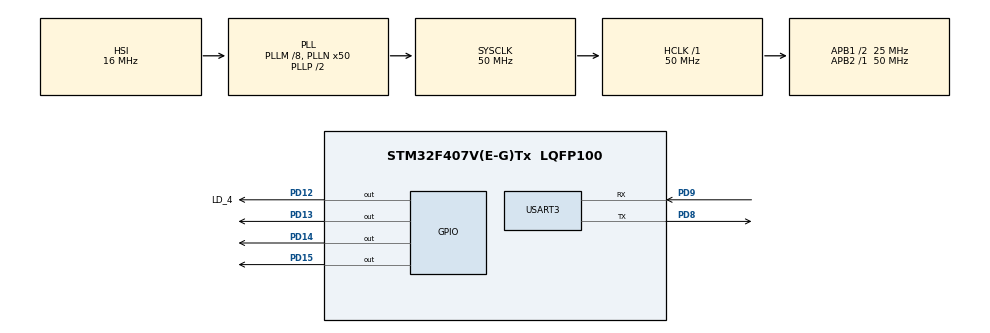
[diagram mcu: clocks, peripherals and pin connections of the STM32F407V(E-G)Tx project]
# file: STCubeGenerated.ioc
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Mcu.Family=STM32F4
Mcu.Name=STM32F407V(E-G)Tx
Mcu.Package=LQFP100
NVIC.PriorityGroup=NVIC_PRIORITYGROUP_4
NVIC.TIM3_IRQn=true\:0\:0\:false\:false\:true\:true\:true
PD12.GPIO_Label=LD_4
PD12.Signal=GPIO_Output
PD13.Signal=GPIO_Output
PD14.Signal=GPIO_Output
PD15.Signal=GPIO_Output
PD8.Mode=Asynchronous
PD8.Signal=USART3_TX
PD9.Mode=Asynchronous
PD9.Signal=USART3_RX
ProjectManager.HeapSize=0x200
ProjectManager.StackSize=0x400
ProjectManager.TargetToolchain=MDK-ARM V5
RCC.48MHZClocksFreq_Value=25000000
RCC.AHBFreq_Value=50000000
RCC.APB1CLKDivider=RCC_HCLK_DIV2
RCC.APB1Freq_Value=25000000
RCC.APB1TimFreq_Value=50000000
RCC.APB2Freq_Value=50000000
RCC.APB2TimFreq_Value=50000000
RCC.CortexFreq_Value=50000000
RCC.HCLKFreq_Value=50000000
RCC.HSE_VALUE=25000000
RCC.HSI_VALUE=16000000
RCC.LSE_VALUE=32768
RCC.PLLM=8
RCC.PLLN=50
RCC.SYSCLKFreq_VALUE=50000000
RCC.SYSCLKSource=RCC_SYSCLKSOURCE_PLLCLK
RCC.VCOOutputFreq_Value=100000000
USART3.VirtualMode=VM_ASYNC
VP_TIM3_VS_ClockSourceINT.Mode=Internal
board=custom

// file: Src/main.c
/* USER CODE BEGIN Header */
/**
  ******************************************************************************
  * @file           : main.c
  * @brief          : Main program body
  ******************************************************************************
  * @attention
  *
  * <h2><center>&copy; Copyright (c) 2021 STMicroelectronics.
  * All rights reserved.</center></h2>
  *
  * This software component is licensed by ST under BSD 3-Clause license,
  * the "License"; You may not use this file except in compliance with the
  * License. You may obtain a copy of the License at:
  *                        opensource.org/licenses/BSD-3-Clause
  *
  ******************************************************************************
  */
/* USER CODE END Header */
#include "main.h"

#include "arm_math.h"
#include <string.h>

#define NO_OF_CLASSES 2			// output classes
#define VECTOR_DIMENSION 2  // input array dimension

const float32_t theta[NO_OF_CLASSES*VECTOR_DIMENSION] = {
  1.6f, 1.2f, 0.7777777777777778f, 1.1111111111111112f
}; /**< Mean values for the Gaussians */

const float32_t sigma[NO_OF_CLASSES*VECTOR_DIMENSION] = {
  0.24000000069387753f, 0.5600000006938776f, 0.6172839513111615f, 0.7654320994593097f
}; /**< Variances for the Gaussians */

const float32_t classPriors[NO_OF_CLASSES] = {
  0.35714285714285715f, 0.6428571428571429f
}; /**< Class prior probabilities */

const float32_t epsilon = 6.938775510204082e-10f ;

TIM_HandleTypeDef htim3;

UART_HandleTypeDef huart3;

arm_gaussian_naive_bayes_instance_f32 NB_pred;

void SystemClock_Config(void);
static void MX_GPIO_Init(void);
static void MX_TIM3_Init(void);
static void MX_USART3_UART_Init(void);

void HAL_TIM_PeriodElapsedCallback(TIM_HandleTypeDef *htim) ;

// Global Space
char * str  ;
char str2[100] ;

int main(void)
{

  /* Reset of all peripherals, Initializes the Flash interface and the Systick. */
  HAL_Init();

  /* Configure the system clock */
  SystemClock_Config();

  /* Initialize all configured peripherals */
  MX_GPIO_Init();
  MX_TIM3_Init();
  MX_USART3_UART_Init();

	/* Interrupt Based Timer start */
	HAL_TIM_Base_Start_IT(&htim3) ;

	 /* Array of input data */
  float32_t in[2];
	in[0] = 1;       // 2,1 = 0 NO   , 1,0 = 1 YES
  in[1] = 0;

  float32_t result[NO_OF_CLASSES];
  float32_t maxProba;
  uint32_t index;

	NB_pred.numberOfClasses = NO_OF_CLASSES ;
	NB_pred.vectorDimension = VECTOR_DIMENSION;
  NB_pred.theta = theta;
  NB_pred.sigma = sigma;
  NB_pred.classPriors = classPriors;
	NB_pred.epsilon = epsilon ;

  while (1)
  {
		arm_gaussian_naive_bayes_predict_f32(&NB_pred, in, result);  // cal probability of class
		arm_max_f32(result, NO_OF_CLASSES, &maxProba, &index);   // gets max value in an array and its index

		sprintf(str2, "Input Value = %f, %f \n\r",in[0],in[1]);
		HAL_UART_Transmit(&huart3, (uint8_t*)str2, strlen(str2), 100) ;

		sprintf(str2, "Predicted Value = %d\n\r",index);
		HAL_UART_Transmit(&huart3, (uint8_t*)str2, strlen(str2), 100) ;

		str = "Entering sleep mode\n\r\n\r" ;
	  HAL_UART_Transmit(&huart3, (uint8_t*)str, strlen(str), 100) ;
		HAL_SuspendTick() ;   // suspend systick as it runs on interrupts
	  //HAL_GPIO_WritePin(GPIOD, LD4_Pin, GPIO_PIN_RESET) ;

	  HAL_PWR_EnterSLEEPMode(PWR_MAINREGULATOR_ON, PWR_SLEEPENTRY_WFI) ; //interrupt of wakeup

	  HAL_ResumeTick() ;
	  str = "Wakeup from Sleep\n\r" ;
	  HAL_UART_Transmit(&huart3, (uint8_t*)str, strlen(str), 100) ;

  }

}

void HAL_TIM_PeriodElapsedCallback(TIM_HandleTypeDef *htim)
{
	if(htim == &htim3){

	}
}

void SystemClock_Config(void)
{
  RCC_OscInitTypeDef RCC_OscInitStruct = {0};
  RCC_ClkInitTypeDef RCC_ClkInitStruct = {0};

  /** Configure the main internal regulator output voltage
  */
  __HAL_RCC_PWR_CLK_ENABLE();
  __HAL_PWR_VOLTAGESCALING_CONFIG(PWR_REGULATOR_VOLTAGE_SCALE1);
  /** Initializes the RCC Oscillators according to the specified parameters
  * in the RCC_OscInitTypeDef structure.
  */
  RCC_OscInitStruct.OscillatorType = RCC_OSCILLATORTYPE_HSI;
  RCC_OscInitStruct.HSIState = RCC_HSI_ON;
  RCC_OscInitStruct.HSICalibrationValue = RCC_HSICALIBRATION_DEFAULT;
  RCC_OscInitStruct.PLL.PLLState = RCC_PLL_ON;
  RCC_OscInitStruct.PLL.PLLSource = RCC_PLLSOURCE_HSI;
  RCC_OscInitStruct.PLL.PLLM = 8;
  RCC_OscInitStruct.PLL.PLLN = 50;
  RCC_OscInitStruct.PLL.PLLP = RCC_PLLP_DIV2;
  RCC_OscInitStruct.PLL.PLLQ = 4;
  if (HAL_RCC_OscConfig(&RCC_OscInitStruct) != HAL_OK)
  {
    Error_Handler();
  }
  /** Initializes the CPU, AHB and APB buses clocks
  */
  RCC_ClkInitStruct.ClockType = RCC_CLOCKTYPE_HCLK|RCC_CLOCKTYPE_SYSCLK
                              |RCC_CLOCKTYPE_PCLK1|RCC_CLOCKTYPE_PCLK2;
  RCC_ClkInitStruct.SYSCLKSource = RCC_SYSCLKSOURCE_PLLCLK;
  RCC_ClkInitStruct.AHBCLKDivider = RCC_SYSCLK_DIV1;
  RCC_ClkInitStruct.APB1CLKDivider = RCC_HCLK_DIV2;
  RCC_ClkInitStruct.APB2CLKDivider = RCC_HCLK_DIV1;

  if (HAL_RCC_ClockConfig(&RCC_ClkInitStruct, FLASH_LATENCY_1) != HAL_OK)
  {
    Error_Handler();
  }
}

static void MX_TIM3_Init(void)
{

  /* USER CODE BEGIN TIM3_Init 0 */
	// 50Mhz APB1 clk
  /* USER CODE END TIM3_Init 0 */

  TIM_ClockConfigTypeDef sClockSourceConfig = {0};
  TIM_MasterConfigTypeDef sMasterConfig = {0};

  htim3.Instance = TIM3;
  htim3.Init.Prescaler = 4999;
  htim3.Init.CounterMode = TIM_COUNTERMODE_UP;
  htim3.Init.Period = 100;   			//   20000 = 2sec delay 10000 = 1sec,  1ms = 10000/1000 = 10
  htim3.Init.ClockDivision = TIM_CLOCKDIVISION_DIV1;
  htim3.Init.AutoReloadPreload = TIM_AUTORELOAD_PRELOAD_DISABLE;
  if (HAL_TIM_Base_Init(&htim3) != HAL_OK)
  {
    Error_Handler();
  }
  sClockSourceConfig.ClockSource = TIM_CLOCKSOURCE_INTERNAL;
  if (HAL_TIM_ConfigClockSource(&htim3, &sClockSourceConfig) != HAL_OK)
  {
    Error_Handler();
  }
  sMasterConfig.MasterOutputTrigger = TIM_TRGO_RESET;
  sMasterConfig.MasterSlaveMode = TIM_MASTERSLAVEMODE_DISABLE;
  if (HAL_TIMEx_MasterConfigSynchronization(&htim3, &sMasterConfig) != HAL_OK)
  {
    Error_Handler();
  }

}

static void MX_USART3_UART_Init(void)
{

  huart3.Instance = USART3;
  huart3.Init.BaudRate = 115200;
  huart3.Init.WordLength = UART_WORDLENGTH_8B;
  huart3.Init.StopBits = UART_STOPBITS_1;
  huart3.Init.Parity = UART_PARITY_NONE;
  huart3.Init.Mode = UART_MODE_TX_RX;
  huart3.Init.HwFlowCtl = UART_HWCONTROL_NONE;
  huart3.Init.OverSampling = UART_OVERSAMPLING_16;
  if (HAL_UART_Init(&huart3) != HAL_OK)
  {
    Error_Handler();
  }
  /* USER CODE BEGIN USART3_Init 2 */
	HAL_UART_Transmit(&huart3, "UART READY\n\r", 15, 1) ;
  /* USER CODE END USART3_Init 2 */

}

static void MX_GPIO_Init(void)
{
  GPIO_InitTypeDef GPIO_InitStruct = {0};

  /* GPIO Ports Clock Enable */
  __HAL_RCC_GPIOD_CLK_ENABLE();

  /*Configure GPIO pin Output Level */
  HAL_GPIO_WritePin(GPIOD, LD_4_Pin|GPIO_PIN_13|GPIO_PIN_14|GPIO_PIN_15, GPIO_PIN_RESET);

  /*Configure GPIO pins : LD_4_Pin PD13 PD14 PD15 */
  GPIO_InitStruct.Pin = LD_4_Pin|GPIO_PIN_13|GPIO_PIN_14|GPIO_PIN_15;
  GPIO_InitStruct.Mode = GPIO_MODE_OUTPUT_PP;
  GPIO_InitStruct.Pull = GPIO_NOPULL;
  GPIO_InitStruct.Speed = GPIO_SPEED_FREQ_LOW;
  HAL_GPIO_Init(GPIOD, &GPIO_InitStruct);

}

void Error_Handler(void)
{
  __disable_irq();
  while (1)
  {
  }
}

/************************ (C) COPYRIGHT STMicroelectronics *****END OF FILE****/
